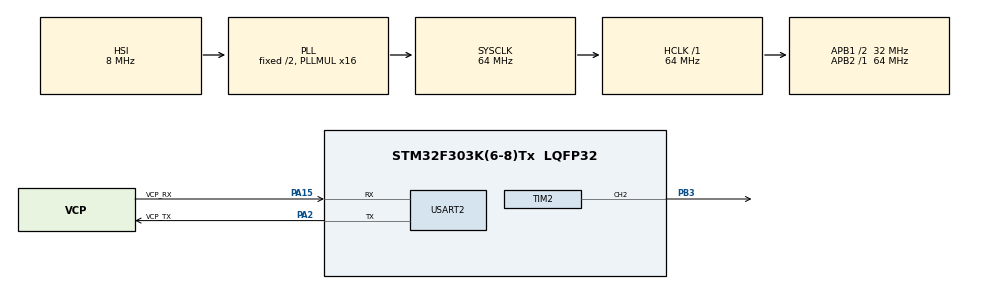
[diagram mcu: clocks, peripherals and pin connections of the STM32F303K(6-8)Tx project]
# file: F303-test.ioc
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Mcu.Family=STM32F3
Mcu.Name=STM32F303K(6-8)Tx
Mcu.Package=LQFP32
NVIC.PriorityGroup=NVIC_PRIORITYGROUP_4
NVIC.TIM3_IRQn=true\:0\:0\:false\:false\:true\:true\:true\:true
PA13.GPIO_Label=SWDIO
PA13.Mode=Serial_Wire
PA13.Signal=SYS_JTMS-SWDIO
PA14.GPIO_Label=SWCLK
PA14.Mode=Serial_Wire
PA14.Signal=SYS_JTCK-SWCLK
PA15.GPIO_Label=VCP_RX
PA15.Mode=Asynchronous
PA15.Signal=USART2_RX
PA2.GPIO_Label=VCP_TX
PA2.Mode=Asynchronous
PA2.Signal=USART2_TX
PB3.Signal=S_TIM2_CH2
PF0\ /\ OSC_IN.GPIO_Label=MCO
PF0\ /\ OSC_IN.Mode=HSE-External-Clock-Source
PF0\ /\ OSC_IN.Signal=RCC_OSC_IN
ProjectManager.HeapSize=0x200
ProjectManager.StackSize=0x400
ProjectManager.TargetToolchain=STM32CubeIDE
RCC.AHBFreq_Value=64000000
RCC.APB1CLKDivider=RCC_HCLK_DIV2
RCC.APB1Freq_Value=32000000
RCC.APB1TimFreq_Value=64000000
RCC.APB2Freq_Value=64000000
RCC.APB2TimFreq_Value=64000000
RCC.CortexFreq_Value=64000000
RCC.DATA_CACHE_ENABLE=1
RCC.HCLKFreq_Value=64000000
RCC.HSE_VALUE=8000000
RCC.HSI_VALUE=8000000
RCC.INSTRUCTION_CACHE_ENABLE=1
RCC.PLLMUL=RCC_PLL_MUL16
RCC.PWREXT_OverDrive=PWREXT_OverDrive_DESACTIVATED
RCC.PWR_Regulator_Voltage_Scale=PWR_REGULATOR_VOLTAGE_SCALE3
RCC.RCC_TIM_PRescaler_Selection=RCC_TIMPRES_DESACTIVATED
RCC.SYSCLKFreq_VALUE=64000000
RCC.SYSCLKSourceVirtual=RCC_SYSCLKSOURCE_PLLCLK
SH.S_TIM2_CH2.0=TIM2_CH2,PWM Generation2 CH2
TIM2.Channel-PWM\ Generation2\ CH2=TIM_CHANNEL_2
TIM2.Period=266
TIM3.Period=1000-1
TIM3.Prescaler=8000-1
USART2.VirtualMode-Asynchronous=VM_ASYNC
VP_TIM2_VS_ClockSourceINT.Mode=Internal
VP_TIM3_VS_ClockSourceINT.Mode=Internal
board=NUCLEO-F303K8

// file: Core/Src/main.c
/* USER CODE BEGIN Header */
/**
  ******************************************************************************
  * @file           : main.c
  * @brief          : Main program body
  ******************************************************************************
  * @attention
  *
  * Copyright (c) 2024 STMicroelectronics.
  * All rights reserved.
  *
  * This software is licensed under terms that can be found in the LICENSE file
  * in the root directory of this software component.
  * If no LICENSE file comes with this software, it is provided AS-IS.
  *
  ******************************************************************************
  */
/* USER CODE END Header */
#include "main.h"

TIM_HandleTypeDef htim2;
TIM_HandleTypeDef htim3;

UART_HandleTypeDef huart2;

void SystemClock_Config(void);
static void MX_GPIO_Init(void);
static void MX_USART2_UART_Init(void);
static void MX_TIM3_Init(void);
static void MX_TIM2_Init(void);

/* USER CODE BEGIN 0 */
void HAL_TIM_PeriodElapsedCallback(TIM_HandleTypeDef *htim){
//    if (htim == &htim3){
//        HAL_GPIO_TogglePin(LED_GPIO_Port, LED_Pin);//ピンの出力を????��?��??��?��???��?��??��?��?り替????��?��??��?��???��?��??��?��?
//    }
}

/* USER CODE END 0 */

int main(void)
{

  /* MCU Configuration--------------------------------------------------------*/

  /* Reset of all peripherals, Initializes the Flash interface and the Systick. */
  HAL_Init();

  /* Configure the system clock */
  SystemClock_Config();

  /* Initialize all configured peripherals */
  MX_GPIO_Init();
  MX_USART2_UART_Init();
  MX_TIM3_Init();
  MX_TIM2_Init();
  /* USER CODE BEGIN 2 */
  HAL_TIM_Base_Start_IT(&htim3);
  /* USER CODE END 2 */

  /* Infinite loop */
  /* USER CODE BEGIN WHILE */
  HAL_TIM_PWM_Start(&htim2, TIM_CHANNEL_2);
  int count = 0, max_step = 265, nagative_flag = 0;

  while (1)
  {
    /* USER CODE END WHILE */

    /* USER CODE BEGIN 3 */
	  if(count >= max_step){
		 nagative_flag = 1;
	  } else if(count <= 0){
		  nagative_flag = 0;
	  }
	  if(nagative_flag) count--;
	  else count++;

	__HAL_TIM_SET_COMPARE(&htim2, TIM_CHANNEL_2, count);
	HAL_Delay(10);
  }
  /* USER CODE END 3 */
}

void SystemClock_Config(void)
{
  RCC_OscInitTypeDef RCC_OscInitStruct = {0};
  RCC_ClkInitTypeDef RCC_ClkInitStruct = {0};

  /** Initializes the RCC Oscillators according to the specified parameters
  * in the RCC_OscInitTypeDef structure.
  */
  RCC_OscInitStruct.OscillatorType = RCC_OSCILLATORTYPE_HSI;
  RCC_OscInitStruct.HSIState = RCC_HSI_ON;
  RCC_OscInitStruct.HSICalibrationValue = RCC_HSICALIBRATION_DEFAULT;
  RCC_OscInitStruct.PLL.PLLState = RCC_PLL_ON;
  RCC_OscInitStruct.PLL.PLLSource = RCC_PLLSOURCE_HSI;
  RCC_OscInitStruct.PLL.PLLMUL = RCC_PLL_MUL16;
  if (HAL_RCC_OscConfig(&RCC_OscInitStruct) != HAL_OK)
  {
    Error_Handler();
  }

  /** Initializes the CPU, AHB and APB buses clocks
  */
  RCC_ClkInitStruct.ClockType = RCC_CLOCKTYPE_HCLK|RCC_CLOCKTYPE_SYSCLK
                              |RCC_CLOCKTYPE_PCLK1|RCC_CLOCKTYPE_PCLK2;
  RCC_ClkInitStruct.SYSCLKSource = RCC_SYSCLKSOURCE_PLLCLK;
  RCC_ClkInitStruct.AHBCLKDivider = RCC_SYSCLK_DIV1;
  RCC_ClkInitStruct.APB1CLKDivider = RCC_HCLK_DIV2;
  RCC_ClkInitStruct.APB2CLKDivider = RCC_HCLK_DIV1;

  if (HAL_RCC_ClockConfig(&RCC_ClkInitStruct, FLASH_LATENCY_2) != HAL_OK)
  {
    Error_Handler();
  }
}

static void MX_TIM2_Init(void)
{

  TIM_ClockConfigTypeDef sClockSourceConfig = {0};
  TIM_MasterConfigTypeDef sMasterConfig = {0};
  TIM_OC_InitTypeDef sConfigOC = {0};

  htim2.Instance = TIM2;
  htim2.Init.Prescaler = 0;
  htim2.Init.CounterMode = TIM_COUNTERMODE_UP;
  htim2.Init.Period = 266;
  htim2.Init.ClockDivision = TIM_CLOCKDIVISION_DIV1;
  htim2.Init.AutoReloadPreload = TIM_AUTORELOAD_PRELOAD_DISABLE;
  if (HAL_TIM_Base_Init(&htim2) != HAL_OK)
  {
    Error_Handler();
  }
  sClockSourceConfig.ClockSource = TIM_CLOCKSOURCE_INTERNAL;
  if (HAL_TIM_ConfigClockSource(&htim2, &sClockSourceConfig) != HAL_OK)
  {
    Error_Handler();
  }
  if (HAL_TIM_PWM_Init(&htim2) != HAL_OK)
  {
    Error_Handler();
  }
  sMasterConfig.MasterOutputTrigger = TIM_TRGO_RESET;
  sMasterConfig.MasterSlaveMode = TIM_MASTERSLAVEMODE_DISABLE;
  if (HAL_TIMEx_MasterConfigSynchronization(&htim2, &sMasterConfig) != HAL_OK)
  {
    Error_Handler();
  }
  sConfigOC.OCMode = TIM_OCMODE_PWM1;
  sConfigOC.Pulse = 0;
  sConfigOC.OCPolarity = TIM_OCPOLARITY_HIGH;
  sConfigOC.OCFastMode = TIM_OCFAST_DISABLE;
  if (HAL_TIM_PWM_ConfigChannel(&htim2, &sConfigOC, TIM_CHANNEL_2) != HAL_OK)
  {
    Error_Handler();
  }
  HAL_TIM_MspPostInit(&htim2);

}

static void MX_TIM3_Init(void)
{

  TIM_ClockConfigTypeDef sClockSourceConfig = {0};
  TIM_MasterConfigTypeDef sMasterConfig = {0};

  htim3.Instance = TIM3;
  htim3.Init.Prescaler = 8000-1;
  htim3.Init.CounterMode = TIM_COUNTERMODE_UP;
  htim3.Init.Period = 1000-1;
  htim3.Init.ClockDivision = TIM_CLOCKDIVISION_DIV1;
  htim3.Init.AutoReloadPreload = TIM_AUTORELOAD_PRELOAD_DISABLE;
  if (HAL_TIM_Base_Init(&htim3) != HAL_OK)
  {
    Error_Handler();
  }
  sClockSourceConfig.ClockSource = TIM_CLOCKSOURCE_INTERNAL;
  if (HAL_TIM_ConfigClockSource(&htim3, &sClockSourceConfig) != HAL_OK)
  {
    Error_Handler();
  }
  sMasterConfig.MasterOutputTrigger = TIM_TRGO_RESET;
  sMasterConfig.MasterSlaveMode = TIM_MASTERSLAVEMODE_DISABLE;
  if (HAL_TIMEx_MasterConfigSynchronization(&htim3, &sMasterConfig) != HAL_OK)
  {
    Error_Handler();
  }

}

static void MX_USART2_UART_Init(void)
{

  huart2.Instance = USART2;
  huart2.Init.BaudRate = 38400;
  huart2.Init.WordLength = UART_WORDLENGTH_8B;
  huart2.Init.StopBits = UART_STOPBITS_1;
  huart2.Init.Parity = UART_PARITY_NONE;
  huart2.Init.Mode = UART_MODE_TX_RX;
  huart2.Init.HwFlowCtl = UART_HWCONTROL_NONE;
  huart2.Init.OverSampling = UART_OVERSAMPLING_16;
  huart2.Init.OneBitSampling = UART_ONE_BIT_SAMPLE_DISABLE;
  huart2.AdvancedInit.AdvFeatureInit = UART_ADVFEATURE_NO_INIT;
  if (HAL_UART_Init(&huart2) != HAL_OK)
  {
    Error_Handler();
  }

}

static void MX_GPIO_Init(void)
{

  /* GPIO Ports Clock Enable */
  __HAL_RCC_GPIOF_CLK_ENABLE();
  __HAL_RCC_GPIOA_CLK_ENABLE();
  __HAL_RCC_GPIOB_CLK_ENABLE();

}

void Error_Handler(void)
{
  __disable_irq();
  while (1)
  {
  }
}
